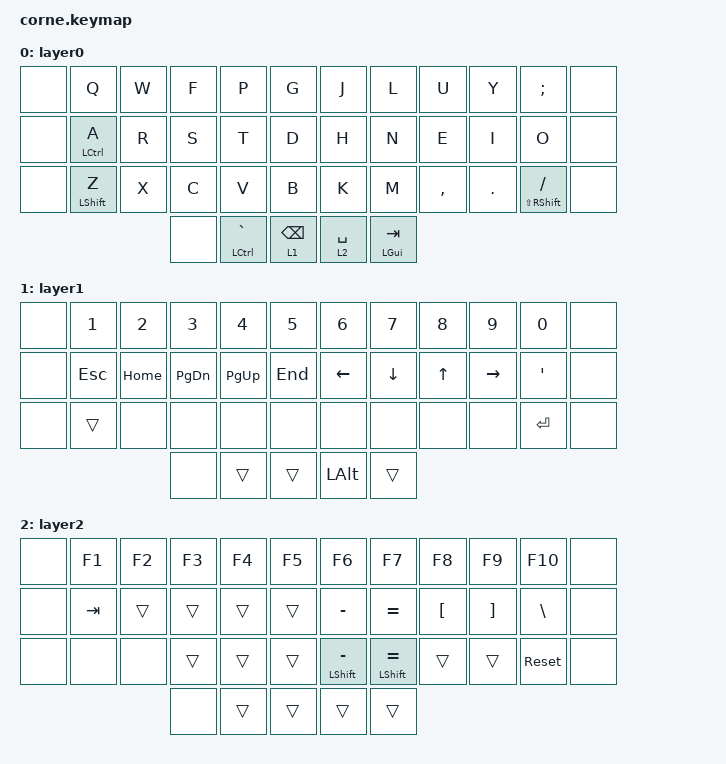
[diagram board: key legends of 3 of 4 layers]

  /*
  * Copyright (c) 2020 The ZMK Contributors
  *
  * SPDX-License-Identifier: MIT
  */

  #include <behaviors.dtsi>
  #include <dt-bindings/zmk/keys.h>
  #include <dt-bindings/zmk/bt.h>
  #include <dt-bindings/zmk/ext_power.h>

  / {
    behaviors {
        bhm: balanced_homerow_mods {
            compatible = "zmk,behavior-hold-tap";
            #binding-cells = <2>;
            tapping-term-ms = <200>;    // <---[[moderate duration]]
            quick-tap-ms = <0>;
            flavor = "balanced";
            bindings = <&kp>, <&kp>;
        };
    };
    keymap {
      compatible = "zmk,keymap";
  layer0 {
          bindings = <
          &none &kp  Q              &kp W &kp F &kp P                  &kp G           &kp J       &kp L           &kp U     &kp Y   &kp SEMICOLON                     &none
          &none &bhm LEFT_CONTROL A &kp R &kp S &kp T                  &kp D           &kp H       &kp N           &kp E     &kp I   &kp O             &none
          &none &mt  LEFT_SHIFT Z   &kp X &kp C &kp V                  &kp B           &kp K       &kp M           &kp COMMA &kp DOT &mt LS(RIGHT_SHIFT) SLASH &none
                                         &none &mt LEFT_CONTROL GRAVE &lt 1 BACKSPACE &lt 2 SPACE &mt LEFT_GUI TAB
          >;
        };layer1 {
          bindings = <
          &none &kp N1     &kp N2   &kp N3        &kp N4      &kp N5  &kp N6       &kp N7   &kp N8 &kp N9    &kp N0           &none
          &none &kp ESCAPE &kp HOME &kp PAGE_DOWN &kp PAGE_UP &kp END &kp LEFT     &kp DOWN &kp UP &kp RIGHT &kp SINGLE_QUOTE &none
          &none &trans     &none    &none         &none       &none   &none        &none    &none  &none     &kp ENTER        &none
                                    &none         &trans      &trans  &kp LEFT_ALT &trans
          >;
        };layer2 {
          bindings = <
          &none &kp F1  &kp F2 &kp F3 &kp F4 &kp F5 &kp F6               &kp F7               &kp F8           &kp F9            &kp F10       &none
          &none &kp TAB &trans &trans &trans &trans &kp MINUS            &kp EQUAL            &kp LEFT_BRACKET &kp RIGHT_BRACKET &kp BACKSLASH &none
          &none &none   &none  &trans &trans &trans &mt LEFT_SHIFT MINUS &mt LEFT_SHIFT EQUAL &trans           &trans            &sys_reset    &none
                               &none  &trans &trans &trans               &trans
          >;
        };layer3 {
          bindings = <
          &trans &trans &trans &trans &trans &trans &trans &trans &trans &trans &trans &trans &trans &trans &trans &trans &trans &none &none &none &trans &trans &trans &trans &trans &trans &trans &trans &trans &trans &trans &trans &trans &trans &trans &trans &trans &none &none &none
          >;
        };
    };
  };
  
